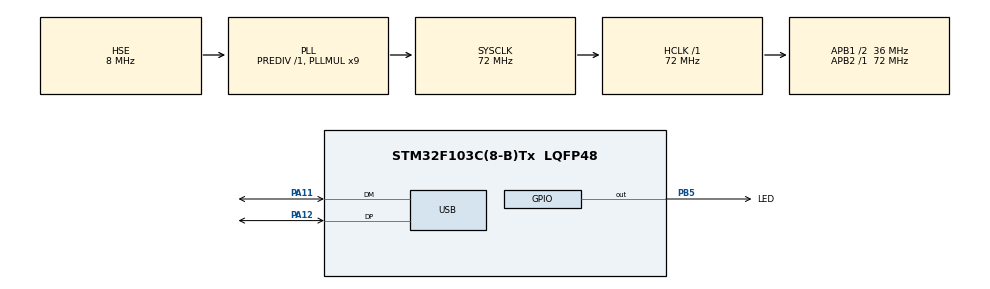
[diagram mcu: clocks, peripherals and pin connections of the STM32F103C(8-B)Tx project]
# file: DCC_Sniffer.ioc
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FREERTOS.Tasks01=defaultTask,24,128,StartDefaultTask,Default,NULL,Dynamic,NULL,NULL
Mcu.Family=STM32F1
Mcu.Name=STM32F103C(8-B)Tx
Mcu.Package=LQFP48
NVIC.PriorityGroup=NVIC_PRIORITYGROUP_4
NVIC.TIM4_IRQn=true\:0\:0\:false\:false\:true\:false\:false\:true
NVIC.TimeBase=TIM4_IRQn
NVIC.TimeBaseIP=TIM4
NVIC.USB_LP_CAN1_RX0_IRQn=true\:5\:0\:false\:false\:true\:true\:false\:true
PA11.Mode=Device
PA11.Signal=USB_DM
PA12.Mode=Device
PA12.Signal=USB_DP
PA13.Mode=Trace_Asynchronous_SW
PA13.Signal=SYS_JTMS-SWDIO
PA14.Mode=Trace_Asynchronous_SW
PA14.Signal=SYS_JTCK-SWCLK
PB3.Mode=Trace_Asynchronous_SW
PB3.Signal=SYS_JTDO-TRACESWO
PB5.GPIO_Label=LED
PB5.Signal=GPIO_Output
PD0-OSC_IN.Mode=HSE-External-Oscillator
PD0-OSC_IN.Signal=RCC_OSC_IN
PD1-OSC_OUT.Mode=HSE-External-Oscillator
PD1-OSC_OUT.Signal=RCC_OSC_OUT
ProjectManager.HeapSize=0x400
ProjectManager.StackSize=0x800
ProjectManager.TargetToolchain=STM32CubeIDE
RCC.AHBFreq_Value=72000000
RCC.APB1CLKDivider=RCC_HCLK_DIV2
RCC.APB1Freq_Value=36000000
RCC.APB1TimFreq_Value=72000000
RCC.APB2Freq_Value=72000000
RCC.APB2TimFreq_Value=72000000
RCC.HCLKFreq_Value=72000000
RCC.PLLMUL=RCC_PLL_MUL9
RCC.SYSCLKFreq_VALUE=72000000
RCC.SYSCLKSource=RCC_SYSCLKSOURCE_PLLCLK
RCC.USBFreq_Value=48000000
RCC.USBPrescaler=RCC_USBCLKSOURCE_PLL_DIV1_5
USB_DEVICE.CLASS_NAME_FS=CDC
USB_DEVICE.MANUFACTURER_STRING=DIY DCC Hardware
USB_DEVICE.PRODUCT_STRING_CDC_FS=DCC Sniffer
USB_DEVICE.VirtualMode=Cdc
USB_DEVICE.VirtualModeFS=Cdc_FS
VP_FREERTOS_VS_CMSIS_V2.Mode=CMSIS_V2
VP_SYS_VS_tim4.Mode=TIM4
VP_USB_DEVICE_VS_USB_DEVICE_CDC_FS.Mode=CDC_FS
board=custom

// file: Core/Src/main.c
/* USER CODE BEGIN Header */
/**
  ******************************************************************************
  * @file           : main.c
  * @brief          : Main program body
  ******************************************************************************
  * @attention
  *
  * <h2><center>&copy; Copyright (c) 2020 STMicroelectronics.
  * All rights reserved.</center></h2>
  *
  * This software component is licensed by ST under BSD 3-Clause license,
  * the "License"; You may not use this file except in compliance with the
  * License. You may obtain a copy of the License at:
  *                        opensource.org/licenses/BSD-3-Clause
  *
  ******************************************************************************
  */
/* USER CODE END Header */

#include "main.h"
#include "cmsis_os.h"
#include "usb_device.h"

/* USER CODE BEGIN Includes */
#include "SerialController.h"
/* USER CODE END Includes */

/* Definitions for defaultTask */
osThreadId_t defaultTaskHandle;
const osThreadAttr_t defaultTask_attributes = {
  .name = "defaultTask",
  .priority = (osPriority_t) osPriorityNormal,
  .stack_size = 128 * 4
};

void SystemClock_Config(void);
static void MX_GPIO_Init(void);
void StartDefaultTask(void *argument);

/* USER CODE BEGIN PFP */
static void USB_Reenumerate(void);
/* USER CODE END PFP */

int main(void)
{

  /* MCU Configuration--------------------------------------------------------*/

  /* Reset of all peripherals, Initializes the Flash interface and the Systick. */
  HAL_Init();

  /* Configure the system clock */
  SystemClock_Config();

  /* Initialize all configured peripherals */
  MX_GPIO_Init();
  /* USER CODE BEGIN 2 */
  USB_Reenumerate();
  /* USER CODE END 2 */

  /* Init scheduler */
  osKernelInitialize();

  /* Create the thread(s) */
  /* creation of defaultTask */
  defaultTaskHandle = osThreadNew(StartDefaultTask, NULL, &defaultTask_attributes);

  /* Start scheduler */
  osKernelStart();

  /* We should never get here as control is now taken by the scheduler */
  /* Infinite loop */
  while (1)
  {

  }
}

void SystemClock_Config(void)
{
  RCC_OscInitTypeDef RCC_OscInitStruct = {0};
  RCC_ClkInitTypeDef RCC_ClkInitStruct = {0};
  RCC_PeriphCLKInitTypeDef PeriphClkInit = {0};

  /** Initializes the CPU, AHB and APB busses clocks
  */
  RCC_OscInitStruct.OscillatorType = RCC_OSCILLATORTYPE_HSE;
  RCC_OscInitStruct.HSEState = RCC_HSE_ON;
  RCC_OscInitStruct.HSEPredivValue = RCC_HSE_PREDIV_DIV1;
  RCC_OscInitStruct.HSIState = RCC_HSI_ON;
  RCC_OscInitStruct.PLL.PLLState = RCC_PLL_ON;
  RCC_OscInitStruct.PLL.PLLSource = RCC_PLLSOURCE_HSE;
  RCC_OscInitStruct.PLL.PLLMUL = RCC_PLL_MUL9;
  if (HAL_RCC_OscConfig(&RCC_OscInitStruct) != HAL_OK)
  {
    Error_Handler();
  }
  /** Initializes the CPU, AHB and APB busses clocks
  */
  RCC_ClkInitStruct.ClockType = RCC_CLOCKTYPE_HCLK|RCC_CLOCKTYPE_SYSCLK
                              |RCC_CLOCKTYPE_PCLK1|RCC_CLOCKTYPE_PCLK2;
  RCC_ClkInitStruct.SYSCLKSource = RCC_SYSCLKSOURCE_PLLCLK;
  RCC_ClkInitStruct.AHBCLKDivider = RCC_SYSCLK_DIV1;
  RCC_ClkInitStruct.APB1CLKDivider = RCC_HCLK_DIV2;
  RCC_ClkInitStruct.APB2CLKDivider = RCC_HCLK_DIV1;

  if (HAL_RCC_ClockConfig(&RCC_ClkInitStruct, FLASH_LATENCY_2) != HAL_OK)
  {
    Error_Handler();
  }
  PeriphClkInit.PeriphClockSelection = RCC_PERIPHCLK_USB;
  PeriphClkInit.UsbClockSelection = RCC_USBCLKSOURCE_PLL_DIV1_5;
  if (HAL_RCCEx_PeriphCLKConfig(&PeriphClkInit) != HAL_OK)
  {
    Error_Handler();
  }
}

static void MX_GPIO_Init(void)
{
  GPIO_InitTypeDef GPIO_InitStruct = {0};

  /* GPIO Ports Clock Enable */
  __HAL_RCC_GPIOD_CLK_ENABLE();
  __HAL_RCC_GPIOA_CLK_ENABLE();
  __HAL_RCC_GPIOB_CLK_ENABLE();

  /*Configure GPIO pin Output Level */
  HAL_GPIO_WritePin(LED_GPIO_Port, LED_Pin, GPIO_PIN_RESET);

  /*Configure GPIO pin : LED_Pin */
  GPIO_InitStruct.Pin = LED_Pin;
  GPIO_InitStruct.Mode = GPIO_MODE_OUTPUT_PP;
  GPIO_InitStruct.Pull = GPIO_NOPULL;
  GPIO_InitStruct.Speed = GPIO_SPEED_FREQ_LOW;
  HAL_GPIO_Init(LED_GPIO_Port, &GPIO_InitStruct);

}

/* USER CODE BEGIN 4 */
static void USB_Reenumerate(void)
{
  GPIO_InitTypeDef GPIO_InitStruct = {0};

  /*Configure GPIO pin Output Level */
  HAL_GPIO_WritePin(GPIOA, GPIO_PIN_12, GPIO_PIN_RESET);

  /*Configure GPIO pin : LED_Pin */
  GPIO_InitStruct.Pin = GPIO_PIN_12;
  GPIO_InitStruct.Mode = GPIO_MODE_OUTPUT_PP;
  GPIO_InitStruct.Pull = GPIO_NOPULL;
  GPIO_InitStruct.Speed = GPIO_SPEED_FREQ_LOW;
  HAL_GPIO_Init(GPIOA, &GPIO_InitStruct);
  /*USB Reset Secuence*/
  HAL_GPIO_WritePin(GPIOA, GPIO_PIN_12, GPIO_PIN_RESET);
  HAL_Delay(1);
  HAL_GPIO_WritePin(GPIOA, GPIO_PIN_12, GPIO_PIN_SET);

}
/* USER CODE END 4 */

void StartDefaultTask(void *argument)
{
  /* init code for USB_DEVICE */
  MX_USB_DEVICE_Init();
  /* USER CODE BEGIN 5 */
  HAL_GPIO_WritePin(LED_GPIO_Port, LED_Pin, GPIO_PIN_SET);
  APP_SerialController_startTask();
  /* Infinite loop */
  for(;;)
  {
	//HAL_GPIO_WritePin(LED_GPIO_Port, LED_Pin, GPIO_PIN_SET);
    osDelay(500);
  }
  /* USER CODE END 5 */
}

 /**
  * @brief  Period elapsed callback in non blocking mode
  * @note   This function is called  when TIM4 interrupt took place, inside
  * HAL_TIM_IRQHandler(). It makes a direct call to HAL_IncTick() to increment
  * a global variable "uwTick" used as application time base.
  * @param  htim : TIM handle
  * @retval None
  */
void HAL_TIM_PeriodElapsedCallback(TIM_HandleTypeDef *htim)
{
  if (htim->Instance == TIM4) {
    HAL_IncTick();
  }
}

void Error_Handler(void)
{
}

/************************ (C) COPYRIGHT STMicroelectronics *****END OF FILE****/
